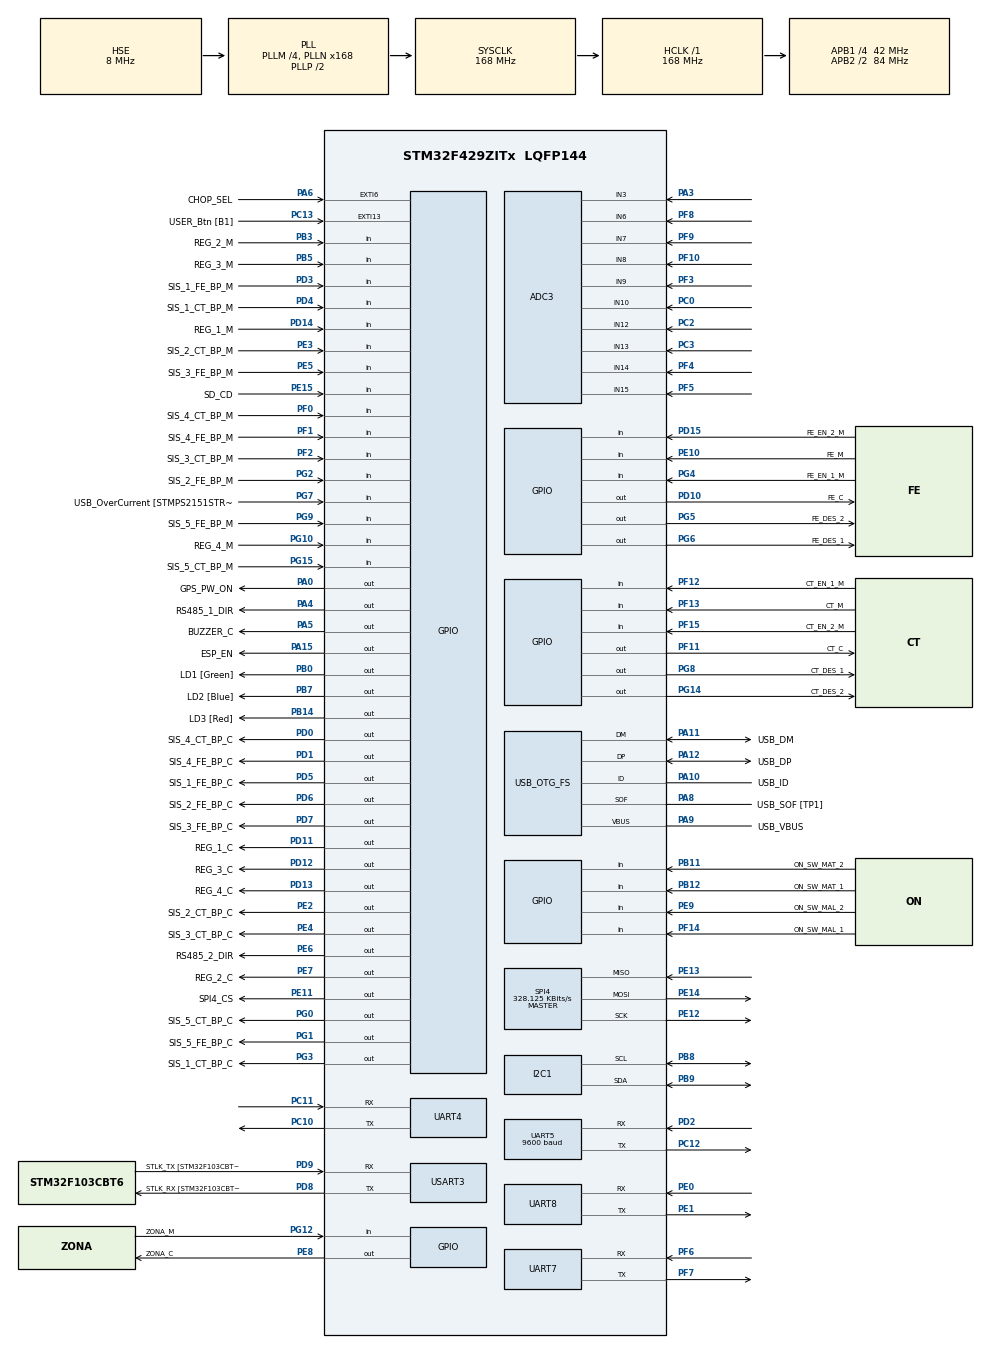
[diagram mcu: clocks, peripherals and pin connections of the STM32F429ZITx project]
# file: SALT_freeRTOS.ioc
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ADC3.Channel-1\#ChannelRegularConversion=ADC_CHANNEL_15
ADC3.Channel-10\#ChannelRegularConversion=ADC_CHANNEL_9
ADC3.Channel-2\#ChannelRegularConversion=ADC_CHANNEL_14
ADC3.Channel-3\#ChannelRegularConversion=ADC_CHANNEL_12
ADC3.Channel-4\#ChannelRegularConversion=ADC_CHANNEL_10
ADC3.Channel-5\#ChannelRegularConversion=ADC_CHANNEL_13
ADC3.Channel-6\#ChannelRegularConversion=ADC_CHANNEL_6
ADC3.Channel-7\#ChannelRegularConversion=ADC_CHANNEL_7
ADC3.Channel-8\#ChannelRegularConversion=ADC_CHANNEL_3
ADC3.Channel-9\#ChannelRegularConversion=ADC_CHANNEL_8
ADC3.ClockPrescaler=ADC_CLOCK_SYNC_PCLK_DIV8
ADC3.EOCSelection=ADC_EOC_SEQ_CONV
ADC3.NbrOfConversion=10
ADC3.NbrOfConversionFlag=1
ADC3.Rank-1\#ChannelRegularConversion=1
ADC3.Rank-10\#ChannelRegularConversion=10
ADC3.Rank-2\#ChannelRegularConversion=2
ADC3.Rank-3\#ChannelRegularConversion=3
ADC3.Rank-4\#ChannelRegularConversion=4
ADC3.Rank-5\#ChannelRegularConversion=5
ADC3.Rank-6\#ChannelRegularConversion=6
ADC3.Rank-7\#ChannelRegularConversion=7
ADC3.Rank-8\#ChannelRegularConversion=8
ADC3.Rank-9\#ChannelRegularConversion=9
ADC3.SamplingTime-1\#ChannelRegularConversion=ADC_SAMPLETIME_480CYCLES
ADC3.SamplingTime-10\#ChannelRegularConversion=ADC_SAMPLETIME_480CYCLES
ADC3.SamplingTime-2\#ChannelRegularConversion=ADC_SAMPLETIME_480CYCLES
ADC3.SamplingTime-3\#ChannelRegularConversion=ADC_SAMPLETIME_480CYCLES
ADC3.SamplingTime-4\#ChannelRegularConversion=ADC_SAMPLETIME_480CYCLES
ADC3.SamplingTime-5\#ChannelRegularConversion=ADC_SAMPLETIME_480CYCLES
ADC3.SamplingTime-6\#ChannelRegularConversion=ADC_SAMPLETIME_480CYCLES
ADC3.SamplingTime-7\#ChannelRegularConversion=ADC_SAMPLETIME_480CYCLES
ADC3.SamplingTime-8\#ChannelRegularConversion=ADC_SAMPLETIME_480CYCLES
ADC3.SamplingTime-9\#ChannelRegularConversion=ADC_SAMPLETIME_480CYCLES
ADC3.ScanConvMode=ENABLE
Dma.ADC3.0.Direction=DMA_PERIPH_TO_MEMORY
Dma.ADC3.0.FIFOMode=DMA_FIFOMODE_DISABLE
Dma.ADC3.0.Instance=DMA2_Stream0
Dma.ADC3.0.MemDataAlignment=DMA_MDATAALIGN_HALFWORD
Dma.ADC3.0.MemInc=DMA_MINC_ENABLE
Dma.ADC3.0.Mode=DMA_NORMAL
Dma.ADC3.0.PeriphDataAlignment=DMA_PDATAALIGN_HALFWORD
Dma.ADC3.0.PeriphInc=DMA_PINC_DISABLE
Dma.ADC3.0.Priority=DMA_PRIORITY_LOW
Dma.Request0=ADC3
FREERTOS.BinarySemaphores01=commsSem,Dynamic,NULL
FREERTOS.Tasks01=modeTransTask,0,512,StartModeTransTask,Default,NULL,Dynamic,NULL,NULL;systemTask,0,1024,StartSystemTask,Default,NULL,Dynamic,NULL,NULL;criticalSigTask,0,512,StartCriticalSigTask,Default,NULL,Dynamic,NULL,NULL;reportTask,-2,256,StartReportTask,Default,NULL,Dynamic,NULL,NULL;commsTask,2,1024,StartCommsTask,Default,NULL,Dynamic,NULL,NULL
FREERTOS.configENABLE_FPU=1
FREERTOS.configUSE_NEWLIB_REENTRANT=1
Mcu.Family=STM32F4
Mcu.Name=STM32F429ZITx
Mcu.Package=LQFP144
NVIC.DMA2_Stream0_IRQn=true\:5\:0\:false\:false\:true\:true\:false\:true\:true
NVIC.EXTI9_5_IRQn=true\:5\:0\:false\:false\:true\:true\:true\:true\:true
NVIC.PriorityGroup=NVIC_PRIORITYGROUP_4
NVIC.TIM1_UP_TIM10_IRQn=true\:0\:0\:true\:false\:true\:false\:false\:true\:true
NVIC.TimeBase=TIM1_UP_TIM10_IRQn
NVIC.TimeBaseIP=TIM1
NVIC.UART4_IRQn=true\:5\:0\:false\:false\:true\:true\:true\:true\:true
NVIC.UART5_IRQn=true\:5\:0\:false\:false\:true\:true\:true\:true\:true
NVIC.UART7_IRQn=true\:5\:0\:false\:false\:true\:true\:true\:true\:true
NVIC.UART8_IRQn=true\:5\:0\:false\:false\:true\:true\:true\:true\:true
NVIC.USART3_IRQn=true\:5\:0\:false\:false\:true\:true\:true\:true\:true
PA0/WKUP.GPIO_Label=GPS_PW_ON
PA0/WKUP.PinState=GPIO_PIN_RESET
PA0/WKUP.Signal=GPIO_Output
PA1.GPIO_Label=RMII_REF_CLK [LAN8742A-CZ-TR_REFCLK0]
PA1.Signal=ETH_REF_CLK
PA10.GPIO_Label=USB_ID
PA10.Mode=OTG/Dual_Role_Device
PA10.Signal=USB_OTG_FS_ID
PA11.GPIO_Label=USB_DM
PA11.Mode=OTG/Dual_Role_Device
PA11.Signal=USB_OTG_FS_DM
PA12.GPIO_Label=USB_DP
PA12.Mode=OTG/Dual_Role_Device
PA12.Signal=USB_OTG_FS_DP
PA13.GPIO_Label=TMS
PA13.Mode=Serial_Wire
PA13.Signal=SYS_JTMS-SWDIO
PA14.GPIO_Label=TCK
PA14.Mode=Serial_Wire
PA14.Signal=SYS_JTCK-SWCLK
PA15.GPIO_Label=ESP_EN
PA15.Signal=GPIO_Output
PA2.GPIO_Label=RMII_MDIO [LAN8742A-CZ-TR_MDIO]
PA2.Signal=ETH_MDIO
PA3.Signal=ADCx_IN3
PA4.GPIO_Label=RS485_1_DIR
PA4.Signal=GPIO_Output
PA5.GPIO_Label=BUZZER_C
PA5.Signal=GPIO_Output
PA6.GPIO_Label=CHOP_SEL
PA6.Signal=GPXTI6
PA7.GPIO_Label=RMII_CRS_DV [LAN8742A-CZ-TR_CRS_DV]
PA7.Signal=ETH_CRS_DV
PA8.GPIO_Label=USB_SOF [TP1]
PA8.Mode=Activate_SOF_FS
PA8.Signal=USB_OTG_FS_SOF
PA9.GPIO_Label=USB_VBUS
PA9.Mode=Activate_VBUS
PA9.Signal=USB_OTG_FS_VBUS
PB0.GPIO_Label=LD1 [Green]
PB0.Signal=GPIO_Output
PB11.GPIO_Label=ON_SW_MAT_2
PB11.Signal=GPIO_Input
PB12.GPIO_Label=ON_SW_MAT_1
PB12.Signal=GPIO_Input
PB13.GPIO_Label=RMII_TXD1 [LAN8742A-CZ-TR_TXD1]
PB13.Signal=ETH_TXD1
PB14.GPIO_Label=LD3 [Red]
PB14.Signal=GPIO_Output
PB3.GPIO_Label=REG_2_M
PB3.Signal=GPIO_Input
PB5.GPIO_Label=REG_3_M
PB5.Signal=GPIO_Input
PB7.GPIO_Label=LD2 [Blue]
PB7.Signal=GPIO_Output
PB8.Mode=I2C
PB8.Signal=I2C1_SCL
PB9.Mode=I2C
PB9.Signal=I2C1_SDA
PC0.Signal=ADCx_IN10
PC1.GPIO_Label=RMII_MDC [LAN8742A-CZ-TR_MDC]
PC1.Signal=ETH_MDC
PC10.Mode=Asynchronous
PC10.Signal=UART4_TX
PC11.Mode=Asynchronous
PC11.Signal=UART4_RX
PC12.Mode=Asynchronous
PC12.Signal=UART5_TX
PC13.GPIO_Label=USER_Btn [B1]
PC13.Signal=GPXTI13
PC14/OSC32_IN.Mode=LSE-External-Oscillator
PC14/OSC32_IN.Signal=RCC_OSC32_IN
PC15/OSC32_OUT.Mode=LSE-External-Oscillator
PC15/OSC32_OUT.Signal=RCC_OSC32_OUT
PC2.Signal=ADCx_IN12
PC3.Signal=ADCx_IN13
PC4.GPIO_Label=RMII_RXD0 [LAN8742A-CZ-TR_RXD0]
PC4.Signal=ETH_RXD0
PC5.GPIO_Label=RMII_RXD1 [LAN8742A-CZ-TR_RXD1]
PC5.Signal=ETH_RXD1
PD0.GPIO_Label=SIS_4_CT_BP_C
PD0.Signal=GPIO_Output
PD1.GPIO_Label=SIS_4_FE_BP_C
PD1.Signal=GPIO_Output
PD10.GPIO_Label=FE_C
PD10.Signal=GPIO_Output
PD11.GPIO_Label=REG_1_C
PD11.Signal=GPIO_Output
PD12.GPIO_Label=REG_3_C
PD12.Signal=GPIO_Output
PD13.GPIO_Label=REG_4_C
PD13.Signal=GPIO_Output
PD14.GPIO_Label=REG_1_M
PD14.Signal=GPIO_Input
PD15.GPIO_Label=FE_EN_2_M
PD15.Signal=GPIO_Input
PD2.Mode=Asynchronous
PD2.Signal=UART5_RX
PD3.GPIO_Label=SIS_1_FE_BP_M
PD3.Signal=GPIO_Input
PD4.GPIO_Label=SIS_1_CT_BP_M
PD4.Signal=GPIO_Input
PD5.GPIO_Label=SIS_1_FE_BP_C
PD5.Signal=GPIO_Output
PD6.GPIO_Label=SIS_2_FE_BP_C
PD6.Signal=GPIO_Output
PD7.GPIO_Label=SIS_3_FE_BP_C
PD7.Signal=GPIO_Output
PD8.GPIO_Label=STLK_RX [STM32F103CBT6_PA3]
PD8.Mode=Asynchronous
PD8.Signal=USART3_TX
PD9.GPIO_Label=STLK_TX [STM32F103CBT6_PA2]
PD9.Mode=Asynchronous
PD9.Signal=USART3_RX
PE0.Mode=Asynchronous
PE0.Signal=UART8_RX
PE1.Mode=Asynchronous
PE1.Signal=UART8_TX
PE10.GPIO_Label=FE_M
PE10.Signal=GPIO_Input
PE11.GPIO_Label=SPI4_CS
PE11.PinState=GPIO_PIN_RESET
PE11.Signal=GPIO_Output
PE12.Mode=Full_Duplex_Master
PE12.Signal=SPI4_SCK
PE13.Mode=Full_Duplex_Master
PE13.Signal=SPI4_MISO
PE14.Mode=Full_Duplex_Master
PE14.Signal=SPI4_MOSI
PE15.GPIO_Label=SD_CD
PE15.Signal=GPIO_Input
PE2.GPIO_Label=SIS_2_CT_BP_C
PE2.Signal=GPIO_Output
PE3.GPIO_Label=SIS_2_CT_BP_M
PE3.Signal=GPIO_Input
PE4.GPIO_Label=SIS_3_CT_BP_C
PE4.Signal=GPIO_Output
PE5.GPIO_Label=SIS_3_FE_BP_M
PE5.Signal=GPIO_Input
PE6.GPIO_Label=RS485_2_DIR
PE6.Signal=GPIO_Output
PE7.GPIO_Label=REG_2_C
PE7.Signal=GPIO_Output
PE8.GPIO_Label=ZONA_C
PE8.Signal=GPIO_Output
PE9.GPIO_Label=ON_SW_MAL_2
PE9.Signal=GPIO_Input
PF0.GPIO_Label=SIS_4_CT_BP_M
PF0.Signal=GPIO_Input
PF1.GPIO_Label=SIS_4_FE_BP_M
PF1.Signal=GPIO_Input
PF10.Mode=IN8
PF10.Signal=ADC3_IN8
PF11.GPIO_Label=CT_C
PF11.Signal=GPIO_Output
PF12.GPIO_Label=CT_EN_1_M
PF12.Signal=GPIO_Input
PF13.GPIO_Label=CT_M
PF13.Signal=GPIO_Input
PF14.GPIO_Label=ON_SW_MAL_1
PF14.Signal=GPIO_Input
PF15.GPIO_Label=CT_EN_2_M
PF15.Signal=GPIO_Input
PF2.GPIO_Label=SIS_3_CT_BP_M
PF2.Signal=GPIO_Input
PF3.Mode=IN9
PF3.Signal=ADC3_IN9
PF4.Mode=IN14
PF4.Signal=ADC3_IN14
PF5.Mode=IN15
PF5.Signal=ADC3_IN15
PF6.Mode=Asynchronous
PF6.Signal=UART7_RX
PF7.Mode=Asynchronous
PF7.Signal=UART7_TX
PF8.Mode=IN6
PF8.Signal=ADC3_IN6
PF9.Mode=IN7
PF9.Signal=ADC3_IN7
PG0.GPIO_Label=SIS_5_CT_BP_C
PG0.Signal=GPIO_Output
PG1.GPIO_Label=SIS_5_FE_BP_C
PG1.Signal=GPIO_Output
PG10.GPIO_Label=REG_4_M
PG10.Signal=GPIO_Input
PG11.GPIO_Label=RMII_TX_EN [LAN8742A-CZ-TR_TXEN]
PG11.Signal=ETH_TX_EN
PG12.GPIO_Label=ZONA_M
PG12.Signal=GPIO_Input
PG13.GPIO_Label=RMII_TXD0 [LAN8742A-CZ-TR_TXD0]
PG13.Signal=ETH_TXD0
PG14.GPIO_Label=CT_DES_2
PG14.Signal=GPIO_Output
PG15.GPIO_Label=SIS_5_CT_BP_M
PG15.Signal=GPIO_Input
PG2.GPIO_Label=SIS_2_FE_BP_M
PG2.Signal=GPIO_Input
PG3.GPIO_Label=SIS_1_CT_BP_C
PG3.Signal=GPIO_Output
PG4.GPIO_Label=FE_EN_1_M
PG4.Signal=GPIO_Input
PG5.GPIO_Label=FE_DES_2
PG5.Signal=GPIO_Output
PG6.GPIO_Label=FE_DES_1
PG6.Signal=GPIO_Output
PG7.GPIO_Label=USB_OverCurrent [STMPS2151STR_FAULT]
PG7.Signal=GPIO_Input
PG8.GPIO_Label=CT_DES_1
PG8.Signal=GPIO_Output
PG9.GPIO_Label=SIS_5_FE_BP_M
PG9.Signal=GPIO_Input
PH0/OSC_IN.GPIO_Label=MCO [STM32F103CBT6_PA8]
PH0/OSC_IN.Mode=HSE-External-Oscillator
PH0/OSC_IN.Signal=RCC_OSC_IN
PH1/OSC_OUT.Mode=HSE-External-Oscillator
PH1/OSC_OUT.Signal=RCC_OSC_OUT
ProjectManager.HeapSize=0x200
ProjectManager.StackSize=0x400
ProjectManager.TargetToolchain=STM32CubeIDE
RCC.48MHZClocksFreq_Value=48000000
RCC.AHBFreq_Value=168000000
RCC.APB1CLKDivider=RCC_HCLK_DIV4
RCC.APB1Freq_Value=42000000
RCC.APB1TimFreq_Value=84000000
RCC.APB2CLKDivider=RCC_HCLK_DIV2
RCC.APB2Freq_Value=84000000
RCC.APB2TimCLKDivider=2
RCC.APB2TimFreq_Value=168000000
RCC.CortexFreq_Value=168000000
RCC.HCLKFreq_Value=168000000
RCC.HSE_VALUE=8000000
RCC.HSI_VALUE=16000000
RCC.PLLM=4
RCC.PLLMUL=RCC_PLL_MUL9
RCC.PLLN=168
RCC.PLLQ=7
RCC.PRESCALERUSB=RCC_USBCLKSOURCE_PLL_DIV1_5
RCC.RCC_RTC_Clock_Source=RCC_RTCCLKSOURCE_LSE
RCC.RCC_RTC_Clock_SourceVirtual=RCC_RTCCLKSOURCE_LSE
RCC.SYSCLKFreq_VALUE=168000000
RCC.SYSCLKSource=RCC_SYSCLKSOURCE_PLLCLK
RCC.SYSCLKSourceVirtual=RCC_SYSCLKSOURCE_PLLCLK
RCC.USBFreq_Value=48000000
RCC.VCOOutputFreq_Value=336000000
SH.ADCx_IN10.0=ADC3_IN10,IN10
SH.ADCx_IN12.0=ADC3_IN12,IN12
SH.ADCx_IN13.0=ADC3_IN13,IN13
SH.ADCx_IN3.0=ADC3_IN3,IN3
SPI4.BaudRatePrescaler=SPI_BAUDRATEPRESCALER_256
SPI4.CalculateBaudRate=328.125 KBits/s
SPI4.Direction=SPI_DIRECTION_2LINES
SPI4.Mode=SPI_MODE_MASTER
SPI4.VirtualType=VM_MASTER
UART4.VirtualMode=Asynchronous
UART5.BaudRate=9600
UART5.VirtualMode=Asynchronous
UART7.VirtualMode=Asynchronous
UART8.VirtualMode=Asynchronous
USART3.VirtualMode=VM_ASYNC
VP_FATFS_VS_Generic.Mode=User_defined
VP_FREERTOS_VS_CMSIS_V1.Mode=CMSIS_V1
VP_RTC_VS_RTC_Activate.Mode=RTC_Enabled
VP_RTC_VS_RTC_Calendar.Mode=RTC_Calendar
VP_SYS_VS_tim1.Mode=TIM1
board=NUCLEO-F429ZI

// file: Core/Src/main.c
/* USER CODE BEGIN Header */
/**
 ******************************************************************************
 * @file           : main.c
 * @brief          : Main program body
 ******************************************************************************
 * @attention
 *
 * Copyright (c) 2023 STMicroelectronics.
 * All rights reserved.
 *
 * This software is licensed under terms that can be found in the LICENSE file
 * in the root directory of this software component.
 * If no LICENSE file comes with this software, it is provided AS-IS.
 *
 ******************************************************************************
 */
/* USER CODE END Header */
#include "main.h"
#include "cmsis_os.h"
#include "fatfs.h"

/* USER CODE BEGIN Includes */
#include "stdio.h"
#include "string.h"
#include "gps.h"
#include "sd.h"
#include "led_driver.h"

#include "globals.h"

/* USER CODE END Includes */

ADC_HandleTypeDef hadc3;
DMA_HandleTypeDef hdma_adc3;

I2C_HandleTypeDef hi2c1;

RTC_HandleTypeDef hrtc;

SPI_HandleTypeDef hspi4;

UART_HandleTypeDef huart4;
UART_HandleTypeDef huart5;
UART_HandleTypeDef huart7;
UART_HandleTypeDef huart8;
UART_HandleTypeDef huart3;

osThreadId modeTransTaskHandle;
osThreadId systemTaskHandle;
osThreadId criticalSigTaskHandle;
osThreadId reportTaskHandle;
osThreadId commsTaskHandle;
osSemaphoreId commsSemHandle;
/* USER CODE BEGIN PV */
const char *salt_mode_labels[] = SALT_MODE_LABELS;
const char *local_log_file_name = "registro.txt";

salt_mode_t salt_mode = MODO_NORMAL;
status_t internal_error = STATUS_OK;

uint8_t report_status_period_s = REPORT_STATUS_PERIOD_S;
uint8_t command_validity_s = COMMAND_VALIDITY_INITIAL;
uint8_t speed_configs[4][4] = {
    NO_ZONE_SPEED_CONFIG_INITIAL,
    ZONE_1_SPEED_CONFIG_INITIAL,
    ZONE_2_SPEED_CONFIG_INITIAL,
    ZONE_3_SPEED_CONFIG_INITIAL};

uint8_t chop_profile_config[5][4] = {
    CHOP_PROFILE_1_INITIAL,
    CHOP_PROFILE_2_INITIAL,
    CHOP_PROFILE_3_INITIAL,
    CHOP_PROFILE_4_INITIAL,
    CHOP_PROFILE_5_INITIAL};

FATFS fs;
char remote_command[MAX_COMMAND_LENGTH];
command_states_t remote_command_active;

comm_t commToProcess = NO_COMM;

char WIFIline[MAX_BUFFER_LENGTH];
char GPSline[MAX_COMMAND_LENGTH];
char rs485_1_line[MAX_BUFFER_LENGTH];
char rs485_2_line[MAX_BUFFER_LENGTH];
char localSerial_line[MAX_BUFFER_LENGTH];

char local_log_buffer[MAX_LOG_LENGTH];
uint32_t gps_dataMillis = 0;
uint32_t rs485_1_dataMillis = 0;
uint32_t rs485_2_dataMillis = 0;

volatile uint16_t adc_results_dma[10];
volatile uint8_t ADC_ConvCplt = 0;
const int adcChannelCount = sizeof(adc_results_dma) / sizeof(adc_results_dma[0]);
SIS_state_t SIS_state[5];

float speed;
speed_source_t speed_source;
status_t gps_status;
zones_t current_zone;

critical_signal_state_t CT_signal;
critical_signal_state_t FE_signal;

uint32_t modo_limitado_activationMillis = 0;
switch_state_t MAL_switch_state_1 = SWITCH_OFF;
switch_state_t MAL_switch_state_2 = SWITCH_OFF;
switch_state_t MAT_switch_state_1 = SWITCH_OFF;
switch_state_t MAT_switch_state_2 = SWITCH_OFF;
buzzer_state_t buzzer_state = BUZZER_OFF;
chop_profile_t chop_profile = CHOP_PROFILE_0;

/* USER CODE END PV */

void SystemClock_Config(void);
static void MX_GPIO_Init(void);
static void MX_DMA_Init(void);
static void MX_USART3_UART_Init(void);
static void MX_ADC3_Init(void);
static void MX_I2C1_Init(void);
static void MX_RTC_Init(void);
static void MX_SPI4_Init(void);
static void MX_UART4_Init(void);
static void MX_UART5_Init(void);
static void MX_UART7_Init(void);
static void MX_UART8_Init(void);
static void MX_USB_OTG_FS_USB_Init(void);
void StartModeTransTask(void const *argument);
void StartSystemTask(void const *argument);
void StartCriticalSigTask(void const *argument);
void StartReportTask(void const *argument);
void StartCommsTask(void const *argument);

/* USER CODE BEGIN 0 */

// Redirect printf to uart debug
int _write(int file, char *ptr, int len)
{
  HAL_UART_Transmit(&DEBUG_UART_HANDLE, (uint8_t *)ptr, len, HAL_MAX_DELAY);
  return len;
}

void HAL_ADC_ConvCpltCallback(ADC_HandleTypeDef *hadc)
{

  if (hadc->Instance == ADC3)
  {
    ADC_ConvCplt = 1;
    HAL_ADC_Start_DMA(&ADC_HANDLE, (uint32_t *)adc_results_dma, adcChannelCount);
  }
}

void HAL_GPIO_EXTI_Callback(uint16_t GPIO_PIN)
{
  static uint32_t previousMillis = 0;
  uint32_t currentMillis;

  if (GPIO_PIN == CHOP_SEL_Pin)
  {
    if (salt_mode == MODO_LIMITADO)
    {
      currentMillis = HAL_GetTick();
      if (currentMillis - previousMillis > BTN_DEBOUNCE_MS)
      {
        if (chop_profile == CHOP_PROFILE_4)
        {
          chop_profile = CHOP_PROFILE_0;
        }
        else
        {
          chop_profile++;
        }
        sprintf(local_log_buffer, "CHOP_PROFILE_%d", chop_profile + 1);
        Log_Event(local_log_buffer);
        previousMillis = currentMillis;
      }
    }
  }
}

/* USER CODE END 0 */

int main(void)
{

  /* MCU Configuration--------------------------------------------------------*/

  /* Reset of all peripherals, Initializes the Flash interface and the Systick. */
  HAL_Init();

  /* Configure the system clock */
  SystemClock_Config();

  /* Initialize all configured peripherals */
  MX_GPIO_Init();
  MX_DMA_Init();
  MX_USART3_UART_Init();
  MX_ADC3_Init();
  MX_I2C1_Init();
  MX_RTC_Init();
  MX_SPI4_Init();
  MX_UART4_Init();
  MX_UART5_Init();
  MX_UART7_Init();
  MX_UART8_Init();
  MX_USB_OTG_FS_USB_Init();
  MX_FATFS_Init();
  /* USER CODE BEGIN 2 */

  // Set power OK
  WriteCheck_RelayState(REG_POWER_OK_C_GPIO_Port, REG_POWER_OK_C_Pin, RELAY_ENERGIZED,
                        REG_POWER_OK_M_GPIO_Port, REG_POWER_OK_M_Pin);

  mount_filesystem(&fs);
  Log_Event("SD_START_OK");
  Log_Event("POWER_OK");

  Init_Communications();

  // Start first ADC conversion
  HAL_ADC_Start_DMA(&ADC_HANDLE, (uint32_t *)adc_results_dma, adcChannelCount);

  I2C_Reset(&hi2c1);
  HAL_I2C_GetState(&I2C_HANDLE);
  LedDriver_Init(&I2C_HANDLE);

  Led_Init();

  /* USER CODE END 2 */

  /* Create the semaphores(s) */
  /* definition and creation of commsSem */
  osSemaphoreDef(commsSem);
  commsSemHandle = osSemaphoreCreate(osSemaphore(commsSem), 1);

  /* Create the thread(s) */
  /* definition and creation of modeTransTask */
  osThreadDef(modeTransTask, StartModeTransTask, osPriorityNormal, 0, 512);
  modeTransTaskHandle = osThreadCreate(osThread(modeTransTask), NULL);

  /* definition and creation of systemTask */
  osThreadDef(systemTask, StartSystemTask, osPriorityNormal, 0, 1024);
  systemTaskHandle = osThreadCreate(osThread(systemTask), NULL);

  /* definition and creation of criticalSigTask */
  osThreadDef(criticalSigTask, StartCriticalSigTask, osPriorityNormal, 0, 512);
  criticalSigTaskHandle = osThreadCreate(osThread(criticalSigTask), NULL);

  /* definition and creation of reportTask */
  osThreadDef(reportTask, StartReportTask, osPriorityLow, 0, 256);
  reportTaskHandle = osThreadCreate(osThread(reportTask), NULL);

  /* definition and creation of commsTask */
  osThreadDef(commsTask, StartCommsTask, osPriorityHigh, 0, 1024);
  commsTaskHandle = osThreadCreate(osThread(commsTask), NULL);

  /* Start scheduler */
  osKernelStart();

  /* We should never get here as control is now taken by the scheduler */
  /* Infinite loop */
  while (1)
  {

  }
}

void SystemClock_Config(void)
{
  RCC_OscInitTypeDef RCC_OscInitStruct = {0};
  RCC_ClkInitTypeDef RCC_ClkInitStruct = {0};

  /** Configure the main internal regulator output voltage
   */
  __HAL_RCC_PWR_CLK_ENABLE();
  __HAL_PWR_VOLTAGESCALING_CONFIG(PWR_REGULATOR_VOLTAGE_SCALE1);

  /** Initializes the RCC Oscillators according to the specified parameters
   * in the RCC_OscInitTypeDef structure.
   */
  RCC_OscInitStruct.OscillatorType = RCC_OSCILLATORTYPE_HSE | RCC_OSCILLATORTYPE_LSE;
  RCC_OscInitStruct.HSEState = RCC_HSE_ON;
  RCC_OscInitStruct.LSEState = RCC_LSE_ON;
  RCC_OscInitStruct.PLL.PLLState = RCC_PLL_ON;
  RCC_OscInitStruct.PLL.PLLSource = RCC_PLLSOURCE_HSE;
  RCC_OscInitStruct.PLL.PLLM = 4;
  RCC_OscInitStruct.PLL.PLLN = 168;
  RCC_OscInitStruct.PLL.PLLP = RCC_PLLP_DIV2;
  RCC_OscInitStruct.PLL.PLLQ = 7;
  if (HAL_RCC_OscConfig(&RCC_OscInitStruct) != HAL_OK)
  {
    Error_Handler();
  }

  /** Initializes the CPU, AHB and APB buses clocks
   */
  RCC_ClkInitStruct.ClockType = RCC_CLOCKTYPE_HCLK | RCC_CLOCKTYPE_SYSCLK | RCC_CLOCKTYPE_PCLK1 | RCC_CLOCKTYPE_PCLK2;
  RCC_ClkInitStruct.SYSCLKSource = RCC_SYSCLKSOURCE_PLLCLK;
  RCC_ClkInitStruct.AHBCLKDivider = RCC_SYSCLK_DIV1;
  RCC_ClkInitStruct.APB1CLKDivider = RCC_HCLK_DIV4;
  RCC_ClkInitStruct.APB2CLKDivider = RCC_HCLK_DIV2;

  if (HAL_RCC_ClockConfig(&RCC_ClkInitStruct, FLASH_LATENCY_5) != HAL_OK)
  {
    Error_Handler();
  }
}

static void MX_ADC3_Init(void)
{

  ADC_ChannelConfTypeDef sConfig = {0};

  /** Configure the global features of the ADC (Clock, Resolution, Data Alignment and number of conversion)
   */
  hadc3.Instance = ADC3;
  hadc3.Init.ClockPrescaler = ADC_CLOCK_SYNC_PCLK_DIV8;
  hadc3.Init.Resolution = ADC_RESOLUTION_12B;
  hadc3.Init.ScanConvMode = ENABLE;
  hadc3.Init.ContinuousConvMode = DISABLE;
  hadc3.Init.DiscontinuousConvMode = DISABLE;
  hadc3.Init.ExternalTrigConvEdge = ADC_EXTERNALTRIGCONVEDGE_NONE;
  hadc3.Init.ExternalTrigConv = ADC_SOFTWARE_START;
  hadc3.Init.DataAlign = ADC_DATAALIGN_RIGHT;
  hadc3.Init.NbrOfConversion = 10;
  hadc3.Init.DMAContinuousRequests = DISABLE;
  hadc3.Init.EOCSelection = ADC_EOC_SEQ_CONV;
  if (HAL_ADC_Init(&hadc3) != HAL_OK)
  {
    Error_Handler();
  }

  /** Configure for the selected ADC regular channel its corresponding rank in the sequencer and its sample time.
   */
  sConfig.Channel = ADC_CHANNEL_15;
  sConfig.Rank = 1;
  sConfig.SamplingTime = ADC_SAMPLETIME_480CYCLES;
  if (HAL_ADC_ConfigChannel(&hadc3, &sConfig) != HAL_OK)
  {
    Error_Handler();
  }

  /** Configure for the selected ADC regular channel its corresponding rank in the sequencer and its sample time.
   */
  sConfig.Channel = ADC_CHANNEL_14;
  sConfig.Rank = 2;
  if (HAL_ADC_ConfigChannel(&hadc3, &sConfig) != HAL_OK)
  {
    Error_Handler();
  }

  /** Configure for the selected ADC regular channel its corresponding rank in the sequencer and its sample time.
   */
  sConfig.Channel = ADC_CHANNEL_12;
  sConfig.Rank = 3;
  if (HAL_ADC_ConfigChannel(&hadc3, &sConfig) != HAL_OK)
  {
    Error_Handler();
  }

  /** Configure for the selected ADC regular channel its corresponding rank in the sequencer and its sample time.
   */
  sConfig.Channel = ADC_CHANNEL_10;
  sConfig.Rank = 4;
  if (HAL_ADC_ConfigChannel(&hadc3, &sConfig) != HAL_OK)
  {
    Error_Handler();
  }

  /** Configure for the selected ADC regular channel its corresponding rank in the sequencer and its sample time.
   */
  sConfig.Channel = ADC_CHANNEL_13;
  sConfig.Rank = 5;
  if (HAL_ADC_ConfigChannel(&hadc3, &sConfig) != HAL_OK)
  {
    Error_Handler();
  }

  /** Configure for the selected ADC regular channel its corresponding rank in the sequencer and its sample time.
   */
  sConfig.Channel = ADC_CHANNEL_6;
  sConfig.Rank = 6;
  if (HAL_ADC_ConfigChannel(&hadc3, &sConfig) != HAL_OK)
  {
    Error_Handler();
  }

  /** Configure for the selected ADC regular channel its corresponding rank in the sequencer and its sample time.
   */
  sConfig.Channel = ADC_CHANNEL_7;
  sConfig.Rank = 7;
  if (HAL_ADC_ConfigChannel(&hadc3, &sConfig) != HAL_OK)
  {
    Error_Handler();
  }

  /** Configure for the selected ADC regular channel its corresponding rank in the sequencer and its sample time.
   */
  sConfig.Channel = ADC_CHANNEL_3;
  sConfig.Rank = 8;
  if (HAL_ADC_ConfigChannel(&hadc3, &sConfig) != HAL_OK)
  {
    Error_Handler();
  }

  /** Configure for the selected ADC regular channel its corresponding rank in the sequencer and its sample time.
   */
  sConfig.Channel = ADC_CHANNEL_8;
  sConfig.Rank = 9;
  if (HAL_ADC_ConfigChannel(&hadc3, &sConfig) != HAL_OK)
  {
    Error_Handler();
  }

  /** Configure for the selected ADC regular channel its corresponding rank in the sequencer and its sample time.
   */
  sConfig.Channel = ADC_CHANNEL_9;
  sConfig.Rank = 10;
  if (HAL_ADC_ConfigChannel(&hadc3, &sConfig) != HAL_OK)
  {
    Error_Handler();
  }
}

static void MX_I2C1_Init(void)
{

  hi2c1.Instance = I2C1;
  hi2c1.Init.ClockSpeed = 100000;
  hi2c1.Init.DutyCycle = I2C_DUTYCYCLE_2;
  hi2c1.Init.OwnAddress1 = 0;
  hi2c1.Init.AddressingMode = I2C_ADDRESSINGMODE_7BIT;
  hi2c1.Init.DualAddressMode = I2C_DUALADDRESS_DISABLE;
  hi2c1.Init.OwnAddress2 = 0;
  hi2c1.Init.GeneralCallMode = I2C_GENERALCALL_DISABLE;
  hi2c1.Init.NoStretchMode = I2C_NOSTRETCH_DISABLE;
  if (HAL_I2C_Init(&hi2c1) != HAL_OK)
  {
    Error_Handler();
  }

  /** Configure Analogue filter
   */
  if (HAL_I2CEx_ConfigAnalogFilter(&hi2c1, I2C_ANALOGFILTER_ENABLE) != HAL_OK)
  {
    Error_Handler();
  }

  /** Configure Digital filter
   */
  if (HAL_I2CEx_ConfigDigitalFilter(&hi2c1, 0) != HAL_OK)
  {
    Error_Handler();
  }
}

static void MX_RTC_Init(void)
{

  RTC_TimeTypeDef sTime = {0};
  RTC_DateTypeDef sDate = {0};

  /** Initialize RTC Only
   */
  hrtc.Instance = RTC;
  hrtc.Init.HourFormat = RTC_HOURFORMAT_24;
  hrtc.Init.AsynchPrediv = 127;
  hrtc.Init.SynchPrediv = 255;
  hrtc.Init.OutPut = RTC_OUTPUT_DISABLE;
  hrtc.Init.OutPutPolarity = RTC_OUTPUT_POLARITY_HIGH;
  hrtc.Init.OutPutType = RTC_OUTPUT_TYPE_OPENDRAIN;
  if (HAL_RTC_Init(&hrtc) != HAL_OK)
  {
    Error_Handler();
  }

  /** Initialize RTC and set the Time and Date
   */
  sTime.Hours = 0x0;
  sTime.Minutes = 0x0;
  sTime.Seconds = 0x0;
  sTime.DayLightSaving = RTC_DAYLIGHTSAVING_NONE;
  sTime.StoreOperation = RTC_STOREOPERATION_RESET;
  if (HAL_RTC_SetTime(&hrtc, &sTime, RTC_FORMAT_BCD) != HAL_OK)
  {
    Error_Handler();
  }
  sDate.WeekDay = RTC_WEEKDAY_MONDAY;
  sDate.Month = RTC_MONTH_JANUARY;
  sDate.Date = 0x1;
  sDate.Year = 0x0;

  if (HAL_RTC_SetDate(&hrtc, &sDate, RTC_FORMAT_BCD) != HAL_OK)
  {
    Error_Handler();
  }
}

static void MX_SPI4_Init(void)
{

  /* SPI4 parameter configuration*/
  hspi4.Instance = SPI4;
  hspi4.Init.Mode = SPI_MODE_MASTER;
  hspi4.Init.Direction = SPI_DIRECTION_2LINES;
  hspi4.Init.DataSize = SPI_DATASIZE_8BIT;
  hspi4.Init.CLKPolarity = SPI_POLARITY_LOW;
  hspi4.Init.CLKPhase = SPI_PHASE_1EDGE;
  hspi4.Init.NSS = SPI_NSS_SOFT;
  hspi4.Init.BaudRatePrescaler = SPI_BAUDRATEPRESCALER_256;
  hspi4.Init.FirstBit = SPI_FIRSTBIT_MSB;
  hspi4.Init.TIMode = SPI_TIMODE_DISABLE;
  hspi4.Init.CRCCalculation = SPI_CRCCALCULATION_DISABLE;
  hspi4.Init.CRCPolynomial = 10;
  if (HAL_SPI_Init(&hspi4) != HAL_OK)
  {
    Error_Handler();
  }
}

static void MX_UART4_Init(void)
{

  huart4.Instance = UART4;
  huart4.Init.BaudRate = 115200;
  huart4.Init.WordLength = UART_WORDLENGTH_8B;
  huart4.Init.StopBits = UART_STOPBITS_1;
  huart4.Init.Parity = UART_PARITY_NONE;
  huart4.Init.Mode = UART_MODE_TX_RX;
  huart4.Init.HwFlowCtl = UART_HWCONTROL_NONE;
  huart4.Init.OverSampling = UART_OVERSAMPLING_16;
  if (HAL_UART_Init(&huart4) != HAL_OK)
  {
    Error_Handler();
  }
}

static void MX_UART5_Init(void)
{

  huart5.Instance = UART5;
  huart5.Init.BaudRate = 9600;
  huart5.Init.WordLength = UART_WORDLENGTH_8B;
  huart5.Init.StopBits = UART_STOPBITS_1;
  huart5.Init.Parity = UART_PARITY_NONE;
  huart5.Init.Mode = UART_MODE_TX_RX;
  huart5.Init.HwFlowCtl = UART_HWCONTROL_NONE;
  huart5.Init.OverSampling = UART_OVERSAMPLING_16;
  if (HAL_UART_Init(&huart5) != HAL_OK)
  {
    Error_Handler();
  }
}

static void MX_UART7_Init(void)
{

  huart7.Instance = UART7;
  huart7.Init.BaudRate = 115200;
  huart7.Init.WordLength = UART_WORDLENGTH_8B;
  huart7.Init.StopBits = UART_STOPBITS_1;
  huart7.Init.Parity = UART_PARITY_NONE;
  huart7.Init.Mode = UART_MODE_TX_RX;
  huart7.Init.HwFlowCtl = UART_HWCONTROL_NONE;
  huart7.Init.OverSampling = UART_OVERSAMPLING_16;
  if (HAL_UART_Init(&huart7) != HAL_OK)
  {
    Error_Handler();
  }
}

static void MX_UART8_Init(void)
{

  huart8.Instance = UART8;
  huart8.Init.BaudRate = 115200;
  huart8.Init.WordLength = UART_WORDLENGTH_8B;
  huart8.Init.StopBits = UART_STOPBITS_1;
  huart8.Init.Parity = UART_PARITY_NONE;
  huart8.Init.Mode = UART_MODE_TX_RX;
  huart8.Init.HwFlowCtl = UART_HWCONTROL_NONE;
  huart8.Init.OverSampling = UART_OVERSAMPLING_16;
  if (HAL_UART_Init(&huart8) != HAL_OK)
  {
    Error_Handler();
  }
}

static void MX_USART3_UART_Init(void)
{

  huart3.Instance = USART3;
  huart3.Init.BaudRate = 115200;
  huart3.Init.WordLength = UART_WORDLENGTH_8B;
  huart3.Init.StopBits = UART_STOPBITS_1;
  huart3.Init.Parity = UART_PARITY_NONE;
  huart3.Init.Mode = UART_MODE_TX_RX;
  huart3.Init.HwFlowCtl = UART_HWCONTROL_NONE;
  huart3.Init.OverSampling = UART_OVERSAMPLING_16;
  if (HAL_UART_Init(&huart3) != HAL_OK)
  {
    Error_Handler();
  }
}

static void MX_USB_OTG_FS_USB_Init(void)
{

}

static void MX_DMA_Init(void)
{

  /* DMA controller clock enable */
  __HAL_RCC_DMA2_CLK_ENABLE();

  /* DMA interrupt init */
  /* DMA2_Stream0_IRQn interrupt configuration */
  HAL_NVIC_SetPriority(DMA2_Stream0_IRQn, 5, 0);
  HAL_NVIC_EnableIRQ(DMA2_Stream0_IRQn);
}

static void MX_GPIO_Init(void)
{
  GPIO_InitTypeDef GPIO_InitStruct = {0};

  /* GPIO Ports Clock Enable */
  __HAL_RCC_GPIOE_CLK_ENABLE();
  __HAL_RCC_GPIOC_CLK_ENABLE();
  __HAL_RCC_GPIOF_CLK_ENABLE();
  __HAL_RCC_GPIOH_CLK_ENABLE();
  __HAL_RCC_GPIOA_CLK_ENABLE();
  __HAL_RCC_GPIOB_CLK_ENABLE();
  __HAL_RCC_GPIOG_CLK_ENABLE();
  __HAL_RCC_GPIOD_CLK_ENABLE();

  /*Configure GPIO pin Output Level */
  HAL_GPIO_WritePin(GPIOE, SIS_2_CT_BP_C_Pin | SIS_3_CT_BP_C_Pin | RS485_2_DIR_Pin | REG_2_C_Pin | ZONA_C_Pin | SPI4_CS_Pin, GPIO_PIN_RESET);

  /*Configure GPIO pin Output Level */
  HAL_GPIO_WritePin(GPIOA, GPS_PW_ON_Pin | RS485_1_DIR_Pin | BUZZER_C_Pin | ESP_EN_Pin, GPIO_PIN_RESET);

  /*Configure GPIO pin Output Level */
  HAL_GPIO_WritePin(GPIOB, LD1_Pin | LD3_Pin | LD2_Pin, GPIO_PIN_RESET);

  /*Configure GPIO pin Output Level */
  HAL_GPIO_WritePin(CT_C_GPIO_Port, CT_C_Pin, GPIO_PIN_RESET);

  /*Configure GPIO pin Output Level */
  HAL_GPIO_WritePin(GPIOG, SIS_5_CT_BP_C_Pin | SIS_5_FE_BP_C_Pin | SIS_1_CT_BP_C_Pin | FE_DES_2_Pin | FE_DES_1_Pin | CT_DES_1_Pin | CT_DES_2_Pin, GPIO_PIN_RESET);

  /*Configure GPIO pin Output Level */
  HAL_GPIO_WritePin(GPIOD, FE_C_Pin | REG_1_C_Pin | REG_3_C_Pin | REG_4_C_Pin | SIS_4_CT_BP_C_Pin | SIS_4_FE_BP_C_Pin | SIS_1_FE_BP_C_Pin | SIS_2_FE_BP_C_Pin | SIS_3_FE_BP_C_Pin, GPIO_PIN_RESET);

  /*Configure GPIO pins : SIS_2_CT_BP_C_Pin SIS_3_CT_BP_C_Pin RS485_2_DIR_Pin REG_2_C_Pin
                           ZONA_C_Pin SPI4_CS_Pin */
  GPIO_InitStruct.Pin = SIS_2_CT_BP_C_Pin | SIS_3_CT_BP_C_Pin | RS485_2_DIR_Pin | REG_2_C_Pin | ZONA_C_Pin | SPI4_CS_Pin;
  GPIO_InitStruct.Mode = GPIO_MODE_OUTPUT_PP;
  GPIO_InitStruct.Pull = GPIO_NOPULL;
  GPIO_InitStruct.Speed = GPIO_SPEED_FREQ_LOW;
  HAL_GPIO_Init(GPIOE, &GPIO_InitStruct);

  /*Configure GPIO pins : SIS_2_CT_BP_M_Pin SIS_3_FE_BP_M_Pin ON_SW_MAL_2_Pin FE_M_Pin
                           SD_CD_Pin */
  GPIO_InitStruct.Pin = SIS_2_CT_BP_M_Pin | SIS_3_FE_BP_M_Pin | ON_SW_MAL_2_Pin | FE_M_Pin | SD_CD_Pin;
  GPIO_InitStruct.Mode = GPIO_MODE_INPUT;
  GPIO_InitStruct.Pull = GPIO_NOPULL;
  HAL_GPIO_Init(GPIOE, &GPIO_InitStruct);

  /*Configure GPIO pin : USER_Btn_Pin */
  GPIO_InitStruct.Pin = USER_Btn_Pin;
  GPIO_InitStruct.Mode = GPIO_MODE_IT_RISING;
  GPIO_InitStruct.Pull = GPIO_NOPULL;
  HAL_GPIO_Init(USER_Btn_GPIO_Port, &GPIO_InitStruct);

  /*Configure GPIO pins : SIS_4_CT_BP_M_Pin SIS_4_FE_BP_M_Pin SIS_3_CT_BP_M_Pin CT_EN_1_M_Pin
                           CT_M_Pin ON_SW_MAL_1_Pin CT_EN_2_M_Pin */
  GPIO_InitStruct.Pin = SIS_4_CT_BP_M_Pin | SIS_4_FE_BP_M_Pin | SIS_3_CT_BP_M_Pin | CT_EN_1_M_Pin | CT_M_Pin | ON_SW_MAL_1_Pin | CT_EN_2_M_Pin;
  GPIO_InitStruct.Mode = GPIO_MODE_INPUT;
  GPIO_InitStruct.Pull = GPIO_NOPULL;
  HAL_GPIO_Init(GPIOF, &GPIO_InitStruct);

  /*Configure GPIO pins : RMII_MDC_Pin RMII_RXD0_Pin RMII_RXD1_Pin */
  GPIO_InitStruct.Pin = RMII_MDC_Pin | RMII_RXD0_Pin | RMII_RXD1_Pin;
  GPIO_InitStruct.Mode = GPIO_MODE_AF_PP;
  GPIO_InitStruct.Pull = GPIO_NOPULL;
  GPIO_InitStruct.Speed = GPIO_SPEED_FREQ_VERY_HIGH;
  GPIO_InitStruct.Alternate = GPIO_AF11_ETH;
  HAL_GPIO_Init(GPIOC, &GPIO_InitStruct);

  /*Configure GPIO pins : GPS_PW_ON_Pin RS485_1_DIR_Pin BUZZER_C_Pin ESP_EN_Pin */
  GPIO_InitStruct.Pin = GPS_PW_ON_Pin | RS485_1_DIR_Pin | BUZZER_C_Pin | ESP_EN_Pin;
  GPIO_InitStruct.Mode = GPIO_MODE_OUTPUT_PP;
  GPIO_InitStruct.Pull = GPIO_NOPULL;
  GPIO_InitStruct.Speed = GPIO_SPEED_FREQ_LOW;
  HAL_GPIO_Init(GPIOA, &GPIO_InitStruct);

  /*Configure GPIO pins : RMII_REF_CLK_Pin RMII_MDIO_Pin RMII_CRS_DV_Pin */
  GPIO_InitStruct.Pin = RMII_REF_CLK_Pin | RMII_MDIO_Pin | RMII_CRS_DV_Pin;
  GPIO_InitStruct.Mode = GPIO_MODE_AF_PP;
  GPIO_InitStruct.Pull = GPIO_NOPULL;
  GPIO_InitStruct.Speed = GPIO_SPEED_FREQ_VERY_HIGH;
  GPIO_InitStruct.Alternate = GPIO_AF11_ETH;
  HAL_GPIO_Init(GPIOA, &GPIO_InitStruct);

  /*Configure GPIO pin : CHOP_SEL_Pin */
  GPIO_InitStruct.Pin = CHOP_SEL_Pin;
  GPIO_InitStruct.Mode = GPIO_MODE_IT_RISING;
  GPIO_InitStruct.Pull = GPIO_NOPULL;
  HAL_GPIO_Init(CHOP_SEL_GPIO_Port, &GPIO_InitStruct);

  /*Configure GPIO pins : LD1_Pin LD3_Pin LD2_Pin */
  GPIO_InitStruct.Pin = LD1_Pin | LD3_Pin | LD2_Pin;
  GPIO_InitStruct.Mode = GPIO_MODE_OUTPUT_PP;
  GPIO_InitStruct.Pull = GPIO_NOPULL;
  GPIO_InitStruct.Speed = GPIO_SPEED_FREQ_LOW;
  HAL_GPIO_Init(GPIOB, &GPIO_InitStruct);

  /*Configure GPIO pin : CT_C_Pin */
  GPIO_InitStruct.Pin = CT_C_Pin;
  GPIO_InitStruct.Mode = GPIO_MODE_OUTPUT_PP;
  GPIO_InitStruct.Pull = GPIO_NOPULL;
  GPIO_InitStruct.Speed = GPIO_SPEED_FREQ_LOW;
  HAL_GPIO_Init(CT_C_GPIO_Port, &GPIO_InitStruct);

  /*Configure GPIO pins : SIS_5_CT_BP_C_Pin SIS_5_FE_BP_C_Pin SIS_1_CT_BP_C_Pin FE_DES_2_Pin
                           FE_DES_1_Pin CT_DES_1_Pin CT_DES_2_Pin */
  GPIO_InitStruct.Pin = SIS_5_CT_BP_C_Pin | SIS_5_FE_BP_C_Pin | SIS_1_CT_BP_C_Pin | FE_DES_2_Pin | FE_DES_1_Pin | CT_DES_1_Pin | CT_DES_2_Pin;
  GPIO_InitStruct.Mode = GPIO_MODE_OUTPUT_PP;
  GPIO_InitStruct.Pull = GPIO_NOPULL;
  GPIO_InitStruct.Speed = GPIO_SPEED_FREQ_LOW;
  HAL_GPIO_Init(GPIOG, &GPIO_InitStruct);

  /*Configure GPIO pins : ON_SW_MAT_2_Pin ON_SW_MAT_1_Pin REG_2_M_Pin REG_3_M_Pin */
  GPIO_InitStruct.Pin = ON_SW_MAT_2_Pin | ON_SW_MAT_1_Pin | REG_2_M_Pin | REG_3_M_Pin;
  GPIO_InitStruct.Mode = GPIO_MODE_INPUT;
  GPIO_InitStruct.Pull = GPIO_NOPULL;
  HAL_GPIO_Init(GPIOB, &GPIO_InitStruct);

  /*Configure GPIO pin : RMII_TXD1_Pin */
  GPIO_InitStruct.Pin = RMII_TXD1_Pin;
  GPIO_InitStruct.Mode = GPIO_MODE_AF_PP;
  GPIO_InitStruct.Pull = GPIO_NOPULL;
  GPIO_InitStruct.Speed = GPIO_SPEED_FREQ_VERY_HIGH;
  GPIO_InitStruct.Alternate = GPIO_AF11_ETH;
  HAL_GPIO_Init(RMII_TXD1_GPIO_Port, &GPIO_InitStruct);

  /*Configure GPIO pins : FE_C_Pin REG_1_C_Pin REG_3_C_Pin REG_4_C_Pin
                           SIS_4_CT_BP_C_Pin SIS_4_FE_BP_C_Pin SIS_1_FE_BP_C_Pin SIS_2_FE_BP_C_Pin
                           SIS_3_FE_BP_C_Pin */
  GPIO_InitStruct.Pin = FE_C_Pin | REG_1_C_Pin | REG_3_C_Pin | REG_4_C_Pin | SIS_4_CT_BP_C_Pin | SIS_4_FE_BP_C_Pin | SIS_1_FE_BP_C_Pin | SIS_2_FE_BP_C_Pin | SIS_3_FE_BP_C_Pin;
  GPIO_InitStruct.Mode = GPIO_MODE_OUTPUT_PP;
  GPIO_InitStruct.Pull = GPIO_NOPULL;
  GPIO_InitStruct.Speed = GPIO_SPEED_FREQ_LOW;
  HAL_GPIO_Init(GPIOD, &GPIO_InitStruct);

  /*Configure GPIO pins : REG_1_M_Pin FE_EN_2_M_Pin SIS_1_FE_BP_M_Pin SIS_1_CT_BP_M_Pin */
  GPIO_InitStruct.Pin = REG_1_M_Pin | FE_EN_2_M_Pin | SIS_1_FE_BP_M_Pin | SIS_1_CT_BP_M_Pin;
  GPIO_InitStruct.Mode = GPIO_MODE_INPUT;
  GPIO_InitStruct.Pull = GPIO_NOPULL;
  HAL_GPIO_Init(GPIOD, &GPIO_InitStruct);

  /*Configure GPIO pins : SIS_2_FE_BP_M_Pin FE_EN_1_M_Pin USB_OverCurrent_Pin SIS_5_FE_BP_M_Pin
                           REG_4_M_Pin ZONA_M_Pin SIS_5_CT_BP_M_Pin */
  GPIO_InitStruct.Pin = SIS_2_FE_BP_M_Pin | FE_EN_1_M_Pin | USB_OverCurrent_Pin | SIS_5_FE_BP_M_Pin | REG_4_M_Pin | ZONA_M_Pin | SIS_5_CT_BP_M_Pin;
  GPIO_InitStruct.Mode = GPIO_MODE_INPUT;
  GPIO_InitStruct.Pull = GPIO_NOPULL;
  HAL_GPIO_Init(GPIOG, &GPIO_InitStruct);

  /*Configure GPIO pins : USB_SOF_Pin USB_ID_Pin USB_DM_Pin USB_DP_Pin */
  GPIO_InitStruct.Pin = USB_SOF_Pin | USB_ID_Pin | USB_DM_Pin | USB_DP_Pin;
  GPIO_InitStruct.Mode = GPIO_MODE_AF_PP;
  GPIO_InitStruct.Pull = GPIO_NOPULL;
  GPIO_InitStruct.Speed = GPIO_SPEED_FREQ_VERY_HIGH;
  GPIO_InitStruct.Alternate = GPIO_AF10_OTG_FS;
  HAL_GPIO_Init(GPIOA, &GPIO_InitStruct);

  /*Configure GPIO pin : USB_VBUS_Pin */
  GPIO_InitStruct.Pin = USB_VBUS_Pin;
  GPIO_InitStruct.Mode = GPIO_MODE_INPUT;
  GPIO_InitStruct.Pull = GPIO_NOPULL;
  HAL_GPIO_Init(USB_VBUS_GPIO_Port, &GPIO_InitStruct);

  /*Configure GPIO pins : RMII_TX_EN_Pin RMII_TXD0_Pin */
  GPIO_InitStruct.Pin = RMII_TX_EN_Pin | RMII_TXD0_Pin;
  GPIO_InitStruct.Mode = GPIO_MODE_AF_PP;
  GPIO_InitStruct.Pull = GPIO_NOPULL;
  GPIO_InitStruct.Speed = GPIO_SPEED_FREQ_VERY_HIGH;
  GPIO_InitStruct.Alternate = GPIO_AF11_ETH;
  HAL_GPIO_Init(GPIOG, &GPIO_InitStruct);

  /* EXTI interrupt init*/
  HAL_NVIC_SetPriority(EXTI9_5_IRQn, 5, 0);
  HAL_NVIC_EnableIRQ(EXTI9_5_IRQn);

}

void StartModeTransTask(void const *argument)
{
  /* USER CODE BEGIN 5 */
  /* Infinite loop */
  for (;;)
  {

    Handle_SaltMode_Transition();

    osDelay(SYSTEM_TASK_PERIOD_MS + (rand() % 50));
    osThreadYield();
  }
  /* USER CODE END 5 */
}

void StartSystemTask(void const *argument)
{
  /* USER CODE BEGIN StartSystemTask */
  /* Infinite loop */
  for (;;)
  {
    Read_SystemStatus();
    Display_SystemStatus();

    osDelay(SYSTEM_TASK_PERIOD_MS + (rand() % 50));
    osThreadYield();
  }
  /* USER CODE END StartSystemTask */
}

void StartCriticalSigTask(void const *argument)
{
  /* USER CODE BEGIN StartCriticalSigTask */
  /* Infinite loop */
  for (;;)
  {

    Set_CriticalSignals_State();
    Control_CriticalSignals();

    osDelay(SYSTEM_TASK_PERIOD_MS + (rand() % 50));
    osThreadYield();
  }
  /* USER CODE END StartCriticalSigTask */
}

void StartReportTask(void const *argument)
{
  /* USER CODE BEGIN StartReportTask */
  /* Infinite loop */
  for (;;)
  {
    Report_SystemStatus();

    osDelay(report_status_period_s * 1000 + (rand() % 50));
    osThreadYield();
  }
  /* USER CODE END StartReportTask */
}

void StartCommsTask(void const *argument)
{
  /* USER CODE BEGIN StartCommsTask */
  /* Infinite loop */
  for (;;)
  {
    if (xSemaphoreTake(commsSemHandle, portMAX_DELAY) == pdTRUE)
    {
      switch (commToProcess)
      {
      case GPS_COMM:
        Process_GPSline();
        break;

      case WIFI_COMM:
        Process_WIFIline();
        break;

      case RS485_1_COMM:
        Process_RS485_1_line();
        break;

      case RS485_2_COMM:
        Process_RS485_2_line();
        break;

      case LOCAL_SERIAL_COMM:
        Process_LocalSerialLine();
        break;

      default:
        break;
      }
    }
  }
  /* USER CODE END StartCommsTask */
}

void HAL_TIM_PeriodElapsedCallback(TIM_HandleTypeDef *htim)
{
  if (htim->Instance == TIM1)
  {
    HAL_IncTick();
  }
}

void Error_Handler(void)
{
  __disable_irq();
  while (1)
  {
  }
}
